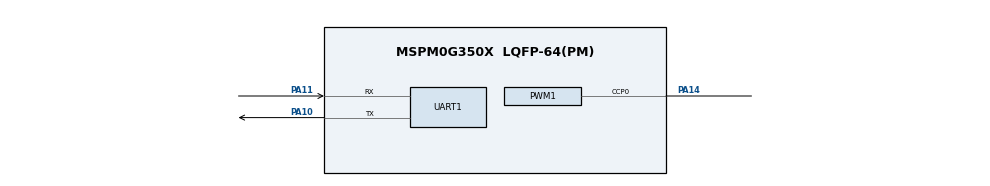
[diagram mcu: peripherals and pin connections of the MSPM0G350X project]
/**
 * @cliArgs --device "MSPM0G350X" --part "Default" --package "LQFP-64(PM)" --product "mspm0_sdk@2.05.00.05"
 * @versions {"tool":"1.24.0+4110"}
 */

/**
 * Import the modules used in this configuration.
 */
const GPIO    = scripting.addModule("/ti/driverlib/GPIO", {}, false);
const GPIO1   = GPIO.addInstance();
const PWM     = scripting.addModule("/ti/driverlib/PWM", {}, false);
const PWM1    = PWM.addInstance();
const SYSCTL  = scripting.addModule("/ti/driverlib/SYSCTL");
const SYSTICK = scripting.addModule("/ti/driverlib/SYSTICK");
const UART    = scripting.addModule("/ti/driverlib/UART", {}, false);
const UART1   = UART.addInstance();

/**
 * Write custom configuration values to the imported modules.
 */
GPIO1.$name                              = "INF_INPUT";
GPIO1.port                               = "PORTA";
GPIO1.associatedPins.create(4);
GPIO1.associatedPins[0].$name            = "L1";
GPIO1.associatedPins[0].direction        = "INPUT";
GPIO1.associatedPins[0].internalResistor = "PULL_UP";
GPIO1.associatedPins[0].assignedPin      = "25";
GPIO1.associatedPins[1].$name            = "L2";
GPIO1.associatedPins[1].direction        = "INPUT";
GPIO1.associatedPins[1].internalResistor = "PULL_UP";
GPIO1.associatedPins[1].assignedPin      = "24";
GPIO1.associatedPins[2].$name            = "R2";
GPIO1.associatedPins[2].direction        = "INPUT";
GPIO1.associatedPins[2].internalResistor = "PULL_UP";
GPIO1.associatedPins[2].assignedPin      = "23";
GPIO1.associatedPins[3].$name            = "R1";
GPIO1.associatedPins[3].direction        = "INPUT";
GPIO1.associatedPins[3].internalResistor = "PULL_UP";
GPIO1.associatedPins[3].assignedPin      = "26";

const Board = scripting.addModule("/ti/driverlib/Board", {}, false);

PWM1.$name                      = "PWM_0";
PWM1.clockDivider               = 8;
PWM1.timerStartTimer            = true;
PWM1.timerCount                 = 80000;
PWM1.ccIndex                    = [0];
PWM1.PWM_CHANNEL_0.$name        = "ti_driverlib_pwm_PWMTimerCC0";
PWM1.PWM_CHANNEL_0.ccValue      = 0;
PWM1.ccp0PinConfig.$name        = "ti_driverlib_gpio_GPIOPinGeneric0";
PWM1.peripheral.$assign         = "TIMG12";
PWM1.peripheral.ccp0Pin.$assign = "PA14";

SYSCTL.forceDefaultClkConfig = true;

SYSTICK.periodEnable    = true;
SYSTICK.period          = 32000;
SYSTICK.systickEnable   = true;
SYSTICK.interruptEnable = true;

UART1.$name                    = "UART_0";
UART1.targetBaudRate           = 115200;
UART1.peripheral.rxPin.$assign = "PA11";
UART1.peripheral.txPin.$assign = "PA10";
UART1.txPinConfig.$name        = "ti_driverlib_gpio_GPIOPinGeneric1";
UART1.rxPinConfig.$name        = "ti_driverlib_gpio_GPIOPinGeneric2";

/**
 * Pinmux solution for unlocked pins/peripherals. This ensures that minor changes to the automatic solver in a future
 * version of the tool will not impact the pinmux you originally saw.  These lines can be completely deleted in order to
 * re-solve from scratch.
 */
GPIO1.associatedPins[0].pin.$suggestSolution = "PA25";
GPIO1.associatedPins[1].pin.$suggestSolution = "PA24";
GPIO1.associatedPins[2].pin.$suggestSolution = "PA23";
GPIO1.associatedPins[3].pin.$suggestSolution = "PA26";
Board.peripheral.$suggestSolution            = "DEBUGSS";
Board.peripheral.swclkPin.$suggestSolution   = "PA20";
Board.peripheral.swdioPin.$suggestSolution   = "PA19";
SYSCTL.peripheral.$suggestSolution           = "SYSCTL";
UART1.peripheral.$suggestSolution            = "UART0";
